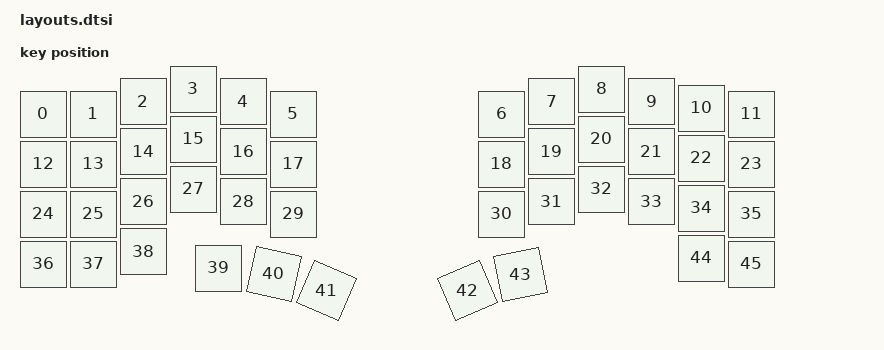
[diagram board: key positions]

#include <physical_layouts.dtsi>
/ {
    physical_layout0: physical_layout0 {
        compatible = "zmk,physical-layout";
        display-name = "Layout";
        keys
            = <&key_physical_attrs 100 100 50 100 0 0 0>
			,<&key_physical_attrs 100 100 150 100 0 0 0>
			,<&key_physical_attrs 100 100 250 75 0 0 0>
			,<&key_physical_attrs 100 100 350 50 0 0 0>
			,<&key_physical_attrs 100 100 450 75 0 0 0>
			,<&key_physical_attrs 100 100 550 100 0 0 0>
			,<&key_physical_attrs 100 100 967 100 0 0 0>
			,<&key_physical_attrs 100 100 1067 75 0 0 0>
			,<&key_physical_attrs 100 100 1167 50 0 0 0>
			,<&key_physical_attrs 100 100 1267 75 0 0 0>
			,<&key_physical_attrs 100 100 1367 88 0 0 0>
			,<&key_physical_attrs 100 100 1467 100 0 0 0>
			,<&key_physical_attrs 100 100 50 200 0 0 0>
			,<&key_physical_attrs 100 100 150 200 0 0 0>
			,<&key_physical_attrs 100 100 250 175 0 0 0>
			,<&key_physical_attrs 100 100 350 150 0 0 0>
			,<&key_physical_attrs 100 100 450 175 0 0 0>
			,<&key_physical_attrs 100 100 550 200 0 0 0>
			,<&key_physical_attrs 100 100 967 200 0 0 0>
			,<&key_physical_attrs 100 100 1067 175 0 0 0>
			,<&key_physical_attrs 100 100 1167 150 0 0 0>
			,<&key_physical_attrs 100 100 1267 175 0 0 0>
			,<&key_physical_attrs 100 100 1367 188 0 0 0>
			,<&key_physical_attrs 100 100 1467 200 0 0 0>
			,<&key_physical_attrs 100 100 50 300 0 0 0>
			,<&key_physical_attrs 100 100 150 300 0 0 0>
			,<&key_physical_attrs 100 100 250 275 0 0 0>
			,<&key_physical_attrs 100 100 350 250 0 0 0>
			,<&key_physical_attrs 100 100 450 275 0 0 0>
			,<&key_physical_attrs 100 100 550 300 0 0 0>
			,<&key_physical_attrs 100 100 967 300 0 0 0>
			,<&key_physical_attrs 100 100 1067 275 0 0 0>
			,<&key_physical_attrs 100 100 1167 250 0 0 0>
			,<&key_physical_attrs 100 100 1267 275 0 0 0>
			,<&key_physical_attrs 100 100 1367 288 0 0 0>
			,<&key_physical_attrs 100 100 1467 300 0 0 0>
			,<&key_physical_attrs 100 100 50 400 0 0 0>
			,<&key_physical_attrs 100 100 150 400 0 0 0>
			,<&key_physical_attrs 100 100 250 375 0 0 0>
			,<&key_physical_attrs 100 100 400 408 0 0 0>
			,<&key_physical_attrs 100 100 523 411 1193 523 411>
			,<&key_physical_attrs 100 100 640 438 2300 640 438>
			,<&key_physical_attrs 100 100 884 477 (-2300) 884 477>
			,<&key_physical_attrs 100 100 996 432 (-1193) 996 432>
			,<&key_physical_attrs 100 100 1367 388 0 0 0>
			,<&key_physical_attrs 100 100 1467 400 0 0 0>
            ;
    };
};
    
